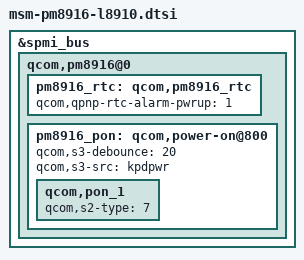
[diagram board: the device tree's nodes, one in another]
/* Copyright (c) 2013-2014, The Linux Foundation. All rights reserved.
 *
 * This program is free software; you can redistribute it and/or modify
 * it under the terms of the GNU General Public License version 2 and
 * only version 2 as published by the Free Software Foundation.
 *
 * This program is distributed in the hope that it will be useful,
 * but WITHOUT ANY WARRANTY; without even the implied warranty of
 * MERCHANTABILITY or FITNESS FOR A PARTICULAR PURPOSE.  See the
 * GNU General Public License for more details.
 */

&spmi_bus {
	qcom,pm8916@0 {
		pm8916_rtc: qcom,pm8916_rtc {
			qcom,qpnp-rtc-alarm-pwrup = <1>;
		};
                pm8916_pon: qcom,power-on@800 {
			qcom,s3-debounce = <20>;
			qcom,s3-src = "kpdpwr";
			qcom,pon_1 {
				qcom,s2-type = <7>;
                        };
		};

	};

};
